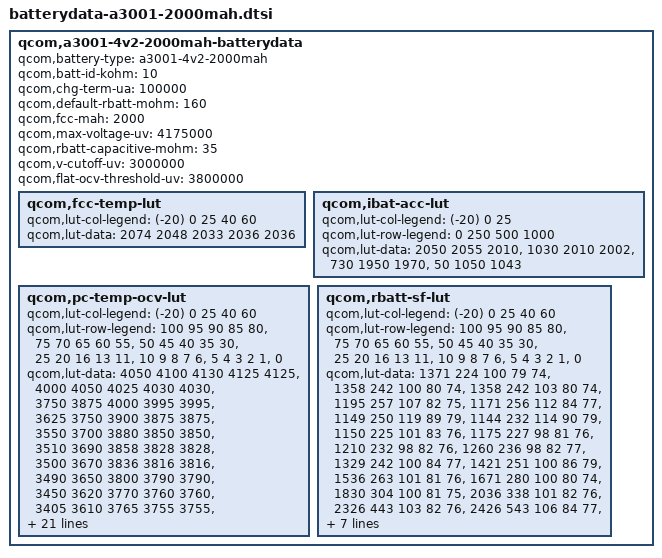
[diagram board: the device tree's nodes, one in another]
/* Copyright (c) 2014, The Linux Foundation. All rights reserved.
 *
 * This program is free software; you can redistribute it and/or modify
 * it under the terms of the GNU General Public License version 2 and
 * only version 2 as published by the Free Software Foundation.
 *
 * This program is distributed in the hope that it will be useful,
 * but WITHOUT ANY WARRANTY; without even the implied warranty of
 * MERCHANTABILITY or FITNESS FOR A PARTICULAR PURPOSE.  See the
 * GNU General Public License for more details.
 */

qcom,a3001-4v2-2000mah-batterydata {
	qcom,battery-type = "a3001-4v2-2000mah";
	qcom,batt-id-kohm = <10>;
	qcom,chg-term-ua = <100000>;
	qcom,default-rbatt-mohm = <160>;
	qcom,fcc-mah = <2000>;
	qcom,max-voltage-uv = <4175000>;
	qcom,rbatt-capacitive-mohm = <35>;
	qcom,v-cutoff-uv = <3000000>;
	qcom,flat-ocv-threshold-uv = <3800000>;

	qcom,fcc-temp-lut {
		qcom,lut-col-legend = <(-20) 0 25 40 60>;
		qcom,lut-data = <2074 2048 2033 2036 2036>;
	};

	qcom,ibat-acc-lut {
		qcom,lut-col-legend = <(-20) 0 25>;
		qcom,lut-row-legend = <0 250 500 1000>;
		qcom,lut-data = <2050 2055 2010>,
				<1030 2010 2002>,
				<730 1950 1970>,
				<50 1050 1043>;
	};

	qcom,pc-temp-ocv-lut {
		qcom,lut-col-legend = <(-20) 0 25 40 60>;
		qcom,lut-row-legend = <100 95 90 85 80>,
					<75 70 65 60 55>,
					<50 45 40 35 30>,
					<25 20 16 13 11>,
					<10 9 8 7 6>,
					<5 4 3 2 1>,
					<0>;
		qcom,lut-data = <4050 4100 4130 4125 4125>,
				<4000 4050 4025 4030 4030>,
				<3750 3875 4000 3995 3995>,
				<3625 3750 3900 3875 3875>,
				<3550 3700 3880 3850 3850>,
				<3510 3690 3858 3828 3828>,
				<3500 3670 3836 3816 3816>,
				<3490 3650 3800 3790 3790>,
				<3450 3620 3770 3760 3760>,
				<3405 3610 3765 3755 3755>,
				<3400 3600 3760 3750 3750>,
				<3390 3590 3755 3745 3745>,
				<3385 3570 3750 3740 3740>,
				<3380 3550 3732 3722 3722>,
				<3375 3500 3724 3714 3714>,
				<3350 3445 3700 3690 3690>,
				<3345 3375 3660 3650 3650>,
				<3340 3350 3650 3600 3600>,
				<3330 3250 3640 3550 3550>,
				<3320 3200 3625 3520 3520>,
				<3310 3125 3600 3500 3500>,
				<3300 3115 3575 3450 3450>,
				<3275 3110 3550 3405 3405>,
				<3250 3098 3525 3360 3360>,
				<3225 3076 3500 3315 3315>,
				<3200 3064 3475 3270 3270>,
				<3175 3062 3450 3235 3235>,
				<3150 3050 3425 3190 3190>,
				<3125 3024 3400 3145 3145>,
				<3100 3012 3375 3100 3100>,
				<3000 3000 3350 3050 3050>;
	};

	qcom,rbatt-sf-lut {
		qcom,lut-col-legend = <(-20) 0 25 40 60>;
		qcom,lut-row-legend = <100 95 90 85 80>,
				      <75 70 65 60 55>,
				      <50 45 40 35 30>,
				      <25 20 16 13 11>,
				      <10 9 8 7 6>,
				      <5 4 3 2 1>,
				      <0>;
		qcom,lut-data = <1371 224 100 79 74>, 
				<1358 242 100 80 74>, 
				<1358 242 103 80 74>, 
				<1195 257 107 82 75>, 
				<1171 256 112 84 77>, 
				<1149 250 119 89 79>, 
				<1144 232 114 90 79>, 
				<1150 225 101 83 76>, 
				<1175 227 98 81 76>,
				<1210 232 98 82 76>,
				<1260 236 98 82 77>,
				<1329 242 100 84 77>, 
				<1421 251 100 86 79>, 
				<1536 263 101 81 76>, 
				<1671 280 100 80 74>,
				<1830 304 100 81 75>,
				<2036 338 101 82 76>,
				<2326 443 103 82 76>,
				<2426 543 106 84 77>,
				<2626 647 110 86 78>,
				<2788 708 112 88 79>,
				<2890 747 115 90 80>,
				<2755 676 117 89 79>,
				<2750 716 118 87 78>,
				<2916 765 119 87 79>,
				<3336 833 123 89 80>,
				<4214 920 133 92 81>,
				<5615 1031 151 96 83>,
				<7923 1188 192 104 89>,
				<13252 1886 585 137 122>,
				<43764 20050 47711 3680 16847>;
	};
};
